# STM32H723 register map
File version: 1.6
CPU: CM7 r0p1, little endian, MPU, FPU, 4 interrupt priority bits
Registers are 32-bit, read-write, reset 0x0 unless marked. A register's access mark holds for its fields unless they carry their own. Offsets are from the block's base; [hi:lo] are bit positions; {n}, {i} and the like mark numbered series.

## SYSCFG — System configuration controller
Base 0x58000400
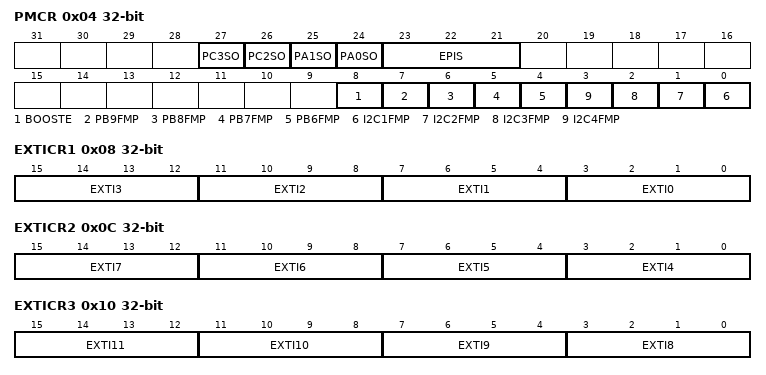
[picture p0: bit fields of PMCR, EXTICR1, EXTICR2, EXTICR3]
0x04 PMCR — peripheral mode configuration register
  [27] PC3SO — PC3 Switch Open
  [26] PC2SO — PC2 Switch Open
  [25] PA1SO — PA1 Switch Open
  [24] PA0SO — PA0 Switch Open
  [23:21] EPIS — Ethernet PHY Interface Selection
  [8] BOOSTE — Booster Enable
  [7] PB9FMP — PB(9) Fm+
  [6] PB8FMP — PB(8) Fast Mode Plus
  [5] PB7FMP — PB(7) Fast Mode Plus
  [4] PB6FMP — PB(6) Fm+
  [n-1] I2C{n}FMP (n=1..4) — I2C{n} Fm+
0x08 EXTICR1 — external interrupt configuration register 1
  [4n+3:4n] EXTI{n} (n=0..3) — EXTI x configuration (x = 0 to 3)
0x0C EXTICR2 — external interrupt configuration register 2
  [4n-13:4n-16] EXTI{n} (n=4..7) — EXTI x configuration (x = 4 to 7)
0x10 EXTICR3 — external interrupt configuration register 3
  [15:12] EXTI11 — EXTI x configuration (x = 8 to 11)
  [11:8] EXTI10
  [7:4] EXTI9 — EXTI x configuration (x = 8 to 11)
  [3:0] EXTI8 — EXTI x configuration (x = 8 to 11)
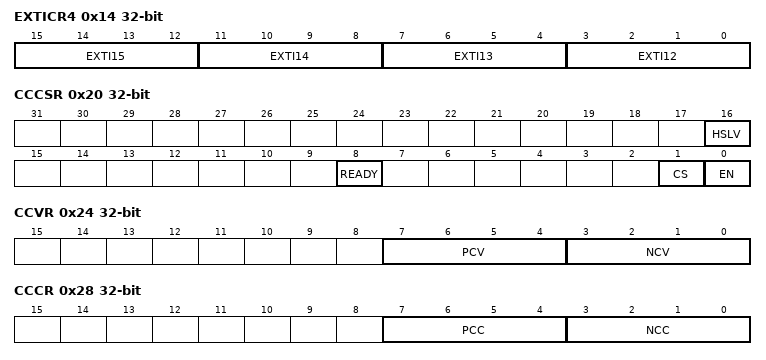
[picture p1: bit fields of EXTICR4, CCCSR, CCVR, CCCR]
0x14 EXTICR4 — external interrupt configuration register 4
  [4n-45:4n-48] EXTI{n} (n=12..15) — EXTI x configuration (x = 12 to 15)
0x20 CCCSR — compensation cell control/status register
  [16] HSLV — High-speed at low-voltage
  [8] READY — Compensation cell ready flag
  [1] CS — Code selection
  [0] EN — enable
0x24 CCVR ro — SYSCFG compensation cell value register
  [7:4] PCV — PMOS compensation value
  [3:0] NCV — NMOS compensation value
0x28 CCCR — SYSCFG compensation cell code register
  [7:4] PCC — PMOS compensation code
  [3:0] NCC — NMOS compensation code
0x124 PKGR ro — SYSCFG package register
  [3:0] PKG — Package
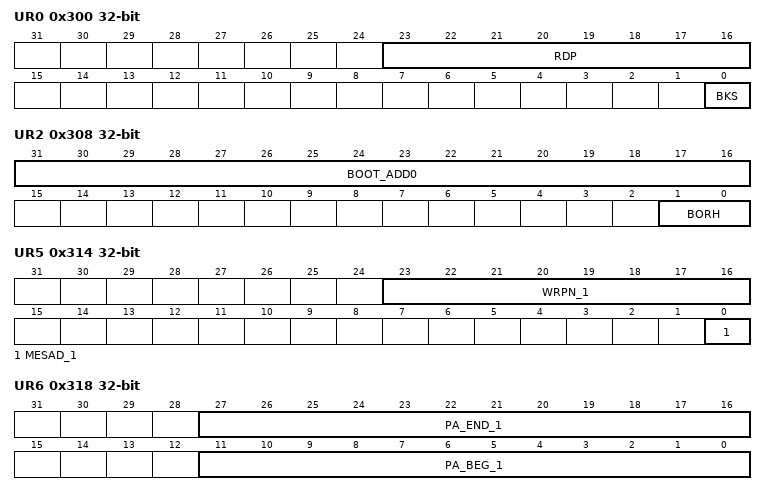
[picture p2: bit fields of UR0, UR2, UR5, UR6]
0x300 UR0 ro — SYSCFG user register 0
  [23:16] RDP — Readout protection
  [0] BKS — Bank Swap
0x308 UR2 — SYSCFG user register 2
  [31:16] BOOT_ADD0 — Boot Address 0
  [1:0] BORH — BOR_LVL Brownout Reset Threshold Level
0x30C UR3 — SYSCFG user register 3
  [31:16] BOOT_ADD1 — Boot Address 1
0x310 UR4 ro — SYSCFG user register 4
  [16] MEPAD_1 — Mass Erase Protected Area Disabled for bank 1
0x314 UR5 ro — SYSCFG user register 5
  [23:16] WRPN_1 — Write protection for flash bank 1
  [0] MESAD_1 — Mass erase secured area disabled for bank 1
0x318 UR6 ro — SYSCFG user register 6
  [27:16] PA_END_1 — Protected area end address for bank 1
  [11:0] PA_BEG_1 — Protected area start address for bank 1
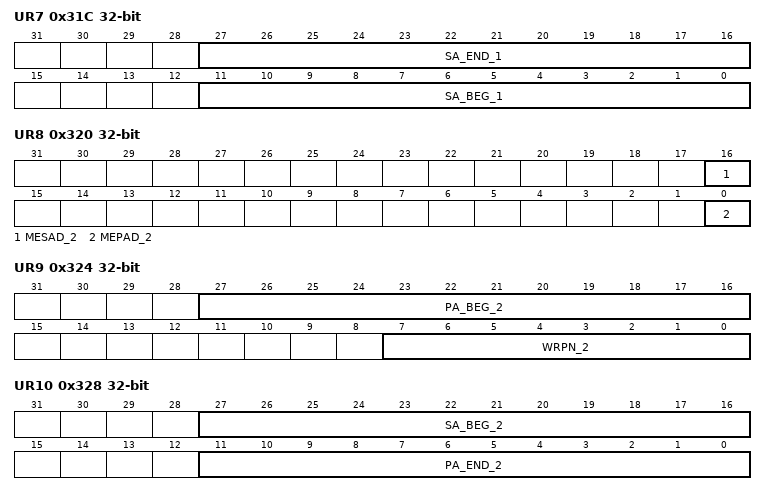
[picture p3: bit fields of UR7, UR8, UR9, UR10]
0x31C UR7 ro — SYSCFG user register 7
  [27:16] SA_END_1 — Secured area end address for bank 1
  [11:0] SA_BEG_1 — Secured area start address for bank 1
0x320 UR8 ro — SYSCFG user register 8
  [16] MESAD_2 — Mass erase secured area disabled for bank 2
  [0] MEPAD_2 — Mass erase protected area disabled for bank 2
0x324 UR9 ro — SYSCFG user register 9
  [27:16] PA_BEG_2 — Protected area start address for bank 2
  [7:0] WRPN_2 — Write protection for flash bank 2
0x328 UR10 ro — SYSCFG user register 10
  [27:16] SA_BEG_2 — Secured area start address for bank 2
  [11:0] PA_END_2 — Protected area end address for bank 2
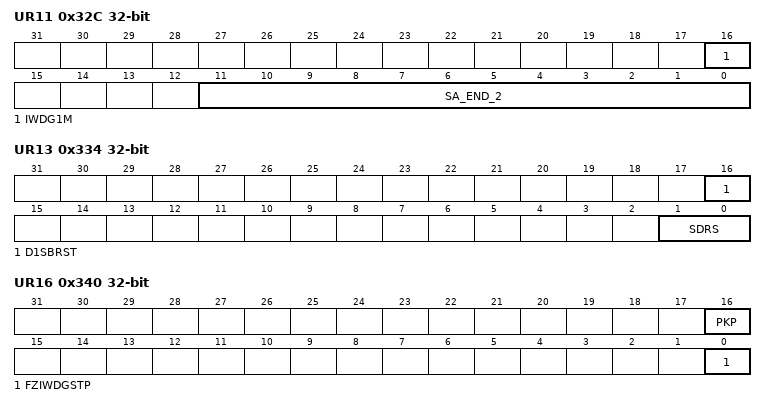
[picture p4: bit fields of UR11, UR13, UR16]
0x32C UR11 ro — SYSCFG user register 11
  [16] IWDG1M — Independent Watchdog 1 mode
  [11:0] SA_END_2 — Secured area end address for bank 2
0x330 UR12 ro — SYSCFG user register 12
  [16] SECURE — Secure mode
0x334 UR13 ro — SYSCFG user register 13
  [16] D1SBRST — D1 Standby reset
  [1:0] SDRS — Secured DTCM RAM Size
0x338 UR14 — SYSCFG user register 14
  [0] D1STPRST — D1 Stop Reset
0x33C UR15 ro — SYSCFG user register 15
  [16] FZIWDGSTB — Freeze independent watchdog in Standby mode
0x340 UR16 ro — SYSCFG user register 16
  [16] PKP — Private key programmed
  [0] FZIWDGSTP — Freeze independent watchdog in Stop mode
0x344 UR17 ro — SYSCFG user register 17
  [0] IO_HSLV — I/O high speed / low voltage

## TIM6 — Basic timers
Base 0x40001000
Same registers: TIM7 0x40001400
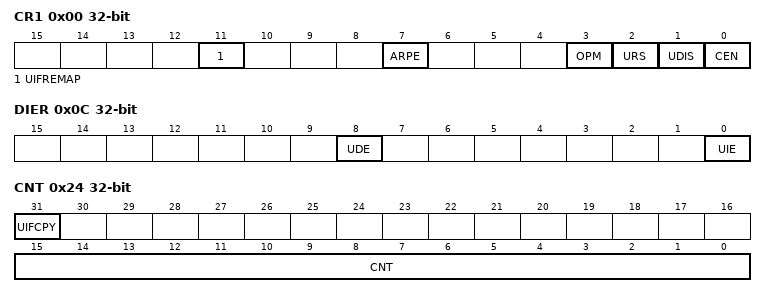
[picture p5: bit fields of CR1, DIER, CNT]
0x00 CR1 — control register 1
  [11] UIFREMAP — UIF status bit remapping
  [7] ARPE — Auto-reload preload enable
  [3] OPM — One-pulse mode
  [2] URS — Update request source
  [1] UDIS — Update disable
  [0] CEN — Counter enable
0x04 CR2 — control register 2
  [6:4] MMS — Master mode selection
0x0C DIER — DMA/Interrupt enable register
  [8] UDE — Update DMA request enable
  [0] UIE — Update interrupt enable
0x10 SR — status register
  [0] UIF — Update interrupt flag
0x14 EGR wo — event generation register
  [0] UG — Update generation
0x24 CNT — counter
  [31] UIFCPY — UIF Copy
  [15:0] CNT — Low counter value
0x28 PSC — prescaler
  [15:0] PSC — Prescaler value
0x2C ARR — auto-reload register
  [15:0] ARR — Low Auto-reload value
